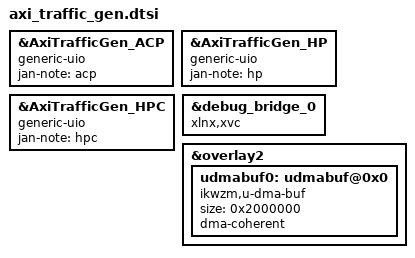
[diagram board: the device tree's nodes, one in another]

&AxiTrafficGen_ACP {
    compatible = "generic-uio";
    jan-note = "acp";
};

&AxiTrafficGen_HP {
    compatible = "generic-uio";
    jan-note = "hp";
};

&AxiTrafficGen_HPC {
    compatible = "generic-uio";
    jan-note = "hpc";
};

&debug_bridge_0 {
    compatible = "xlnx,xvc";
};

&overlay2 {
    udmabuf0: udmabuf@0x0 {
        compatible = "ikwzm,u-dma-buf";
        size = <0x2000000>;
        dma-coherent;
    };
};

